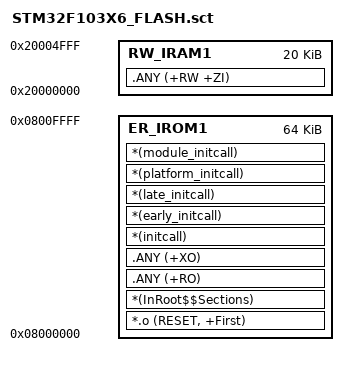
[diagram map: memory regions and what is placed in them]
; *************************************************************
; *** Scatter-Loading Description File generated by uVision ***
; *************************************************************

LR_IROM1 0x08000000 0x00010000  {    ; load region size_region
  ER_IROM1 0x08000000 0x00010000  {  ; load address = execution address
   *.o (RESET, +First)            ; Vector table
   *(InRoot$$Sections)            ; Other startup sections
   .ANY (+RO)                     ; Custom user section
   .ANY (+XO)                     ; Read-Only Data
   ; Custom section for init calls with defined boundaries
   *(initcall)                   ; .initcall section
   *(early_initcall)             ; .early.initcall section
   *(late_initcall)              ; .late.initcall section
   *(platform_initcall)          ; .platform.initcall section
   *(module_initcall)            ; .module.initcall section
  }
  RW_IRAM1 0x20000000 0x00005000  {  ; RW data
   .ANY (+RW +ZI)
  }
}
